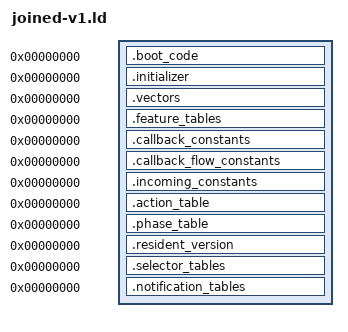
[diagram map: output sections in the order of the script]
OUTPUT_ARCH(riscv)
SECTIONS
{
 .boot_code 0 : SUBALIGN(2) { *(.boot_code)
  *(.text.tsl9_selector_storage_provider_e220)
  *(.text.tsl9_selector_notifications_block_e226)
  *(.text.tsl9_selector_notifications_block_e246)
  *(.text.tsl9_selector_notifications_block_e24a)
  *(.text.tsl9_selector_notifications_block_e252)
  *(.text.tsl9_selector_notifications_block_e254)
  *(.text.tsl9_selector_notifications_block_e260)
  *(.text.tsl9_selector_notifications_block_e26e)
  *(.text.tsl9_selector_notifications_block_e280)
  *(.text.tsl9_selector_notifications_block_e284)
  *(.text.tsl9_selector_notifications_block_e288)
  *(.text.tsl9_selector_notifications_block_e28c)
  *(.text.tsl9_selector_notifications_block_e290)
  *(.text.tsl9_selector_notifications_block_e29c)
  *(.text.tsl9_selector_notifications_block_e2a0)
  *(.text.tsl9_selector_notifications_block_e2a6)
  *(.text.tsl9_selector_notifications_block_e2aa)
  *(.text.tsl9_selector_notifications_block_e2b0)
  *(.text.tsl9_selector_notifications_block_e2b4)
  *(.text.tsl9_selector_notifications_block_e2bc)
  *(.text.tsl9_selector_notifications_block_e2ca)
  *(.text.tsl9_selector_notifications_block_e2da)
  *(.text.tsl9_selector_notifications_block_e2e2)
  *(.text.tsl9_selector_notifications_block_e2e8)
  *(.text.tsl9_selector_notifications_block_e2ea)
  *(.text.tsl9_selector_notifications_block_e2f0)
  *(.text.tsl9_selector_notifications_block_e2f8)
  *(.text.tsl9_selector_notifications_block_e30c)
  *(.text.tsl9_selector_notifications_block_e30e)
  *(.text.tsl9_selector_notifications_block_e310)
  *(.text.tsl9_selector_notifications_block_e314)
  *(.text.tsl9_selector_notifications_block_e316)
  *(.text.tsl9_selector_notifications_block_e31a)
  *(.text.tsl9_selector_notifications_block_e322)
  *(.text.tsl9_selector_notifications_block_e328)
  *(.text.tsl9_selector_notifications_block_e32c)
  *(.text.tsl9_selector_notifications_block_e330)
  *(.text.tsl9_selector_notifications_block_e336)
  *(.text.tsl9_selector_notifications_block_e33c)
  *(.text.tsl9_selector_notifications_block_e342)
  *(.text.tsl9_selector_notifications_block_e34c)
  *(.text.tsl9_selector_notifications_block_e350)
  *(.text.tsl9_selector_notifications_block_e352)
  *(.text.tsl9_selector_notifications_block_e358)
  *(.text.tsl9_selector_notifications_block_e35c)
  *(.text.tsl9_selector_notifications_block_e362)
  *(.text.tsl9_selector_notifications_block_e36c)
  *(.text.tsl9_selector_notifications_block_e36e)
  *(.text.tsl9_selector_notifications_block_e374)
  *(.text.tsl9_selector_notifications_block_e37e)
  *(.text.tsl9_selector_notifications_block_e380)
  *(.text.tsl9_selector_notifications_block_e388)
  *(.text.tsl9_selector_notifications_block_e38c)
  *(.text.tsl9_selector_notifications_block_e394)
  *(.text.tsl9_selector_notifications_block_e398)
  *(.text.tsl9_selector_notifications_block_e3a2)
  *(.text.tsl9_selector_notifications_block_e3a6)
  *(.text.tsl9_selector_notifications_block_e3a8)
  *(.text.tsl9_selector_notifications_block_e3b0)
  *(.text.tsl9_selector_notifications_block_e3bc)
  *(.text.tsl9_selector_notifications_block_e3be)
  *(.text.tsl9_selector_notifications_block_e3c6)
  *(.text.tsl9_selector_notifications_block_e3ca)
  *(.text.tsl9_selector_notifications_block_e3d2)
  *(.text.tsl9_selector_notifications_block_e3dc)
  *(.text.tsl9_selector_notifications_block_e3de)
  *(.text.tsl9_selector_notifications_block_e3e8)
  *(.text.tsl9_selector_notifications_block_e3f0)
  *(.text.tsl9_selector_notifications_block_e3f2)
  *(.text.tsl9_selector_notifications_block_e3f6)
  *(.text.tsl9_selector_notifications_block_e3f8)
  *(.text.tsl9_selector_notifications_block_e3fe)
  *(.text.tsl9_selector_notifications_block_e404)
  *(.text.tsl9_selector_notifications_block_e40a)
  *(.text.tsl9_selector_notifications_block_e410)
  *(.text.tsl9_selector_notifications_block_e416)
  *(.text.tsl9_selector_notifications_block_e41a)
  *(.text.tsl9_selector_notifications_block_e420)
  *(.text.tsl9_selector_notifications_block_e424)
  *(.text.tsl9_selector_notifications_block_e428)
  *(.text.tsl9_selector_notifications_block_e42e)
  *(.text.tsl9_selector_notifications_block_e432)
  *(.text.tsl9_selector_notifications_block_e438)
  *(.text.tsl9_selector_notifications_block_e43c)
  *(.text.tsl9_selector_notifications_block_e442)
  *(.text.tsl9_selector_notifications_block_e446)
  *(.text.tsl9_selector_notifications_block_e44c)
  *(.text.tsl9_selector_notifications_block_e450)
  *(.text.tsl9_selector_notifications_block_e454)
  *(.text.tsl9_selector_notifications_block_e458)
  *(.text.tsl9_selector_notifications_block_e45c)
  *(.text.tsl9_selector_notifications_block_e464)
  *(.text.tsl9_selector_notifications_block_e466)
  *(.text.tsl9_selector_notifications_block_e46c)
  *(.text.tsl9_selector_notifications_block_e472)
  *(.text.tsl9_selector_notifications_block_e47a)
  *(.text.tsl9_selector_notifications_block_e47e)
  *(.text.tsl9_selector_notifications_block_e482)
  *(.text.tsl9_selector_notifications_block_e486)
  *(.text.tsl9_selector_notifications_block_e48e)
  *(.text.tsl9_selector_notifications_block_e492)
  *(.text.tsl9_selector_notifications_block_e49a)
  *(.text.tsl9_selector_notifications_block_e49e)
  *(.text.tsl9_selector_notifications_block_e4a0)
  *(.text.tsl9_selector_notifications_block_e4a8)
  *(.text.tsl9_selector_notifications_block_e4b0)
  *(.text.tsl9_selector_notifications_block_e4b4)
  *(.text.tsl9_selector_notifications_block_e4b6)
  *(.text.tsl9_selector_notifications_block_e4c2)
  *(.text.tsl9_selector_notifications_block_e4c8)
  *(.text.tsl9_selector_notifications_block_e4ca)
  *(.text.tsl9_selector_notifications_block_e4d2)
  *(.text.tsl9_selector_notifications_block_e4d6)
  *(.text.tsl9_selector_notifications_block_e4da)
  *(.text.tsl9_selector_notifications_block_e4de)
  *(.text.tsl9_selector_notifications_block_e4e6)
  *(.text.tsl9_selector_notifications_block_e4ea)
  *(.text.tsl9_selector_notifications_block_e4ee)
  *(.text.tsl9_selector_notifications_block_e4f2)
  *(.text.tsl9_selector_notifications_block_e4fa)
  *(.text.tsl9_selector_notifications_block_e4fe)
  *(.text.tsl9_selector_notifications_block_e502)
  *(.text.tsl9_selector_notifications_block_e506)
  *(.text.tsl9_selector_notifications_block_e50a)
  *(.text.tsl9_selector_notifications_block_e50e)
  *(.text.tsl9_selector_notifications_block_e516)
  *(.text.tsl9_selector_notifications_block_e51a)
  *(.text.tsl9_selector_notifications_block_e520)
  *(.text.tsl9_selector_notifications_block_e524)
  *(.text.tsl9_selector_notifications_block_e532)
  *(.text.tsl9_selector_notifications_block_e53a)
  *(.text.tsl9_selector_notifications_block_e53e)
  *(.text.tsl9_selector_notifications_block_e546)
  *(.text.tsl9_selector_notifications_block_e554)
  *(.text.tsl9_selector_notifications_block_e55c)
  *(.text.tsl9_selector_notifications_block_e560)
  *(.text.tsl9_selector_notifications_block_e568)
  *(.text.tsl9_selector_notifications_block_e570)
  *(.text.tsl9_selector_notifications_block_e578)
  *(.text.tsl9_selector_notifications_block_e580)
  *(.text.tsl9_selector_notifications_block_e584)
  *(.text.tsl9_selector_notifications_block_e592)
  *(.text.tsl9_selector_notifications_block_e59a)
  *(.text.tsl9_selector_notifications_block_e5a2)
  *(.text.tsl9_selector_notifications_block_e5a8)
  *(.text.tsl9_selector_notifications_block_e5ac)
  *(.text.tsl9_selector_notifications_block_e5b0)
  *(.text.tsl9_selector_notifications_block_e5b2)
  *(.text.tsl9_selector_notifications_block_e5ba)
  *(.text.tsl9_selector_notifications_block_e5be)
  *(.text.tsl9_selector_notifications_block_e5c6)
  *(.text.tsl9_selector_notifications_block_e5c8)
  *(.text.tsl9_selector_notifications_block_e5d0)
  *(.text.tsl9_selector_notifications_block_e5d8)
  *(.text.tsl9_selector_notifications_block_e5e8)
  *(.text.tsl9_selector_notifications_block_e5ee)
  *(.text.tsl9_selector_notifications_block_e5f2)
  *(.text.tsl9_selector_notifications_block_e5f6)
  *(.text.tsl9_selector_notifications_block_e5f8)
  *(.text.tsl9_selector_notifications_block_e5fe)
  *(.text.tsl9_selector_notifications_block_e606)
  *(.text.tsl9_selector_notifications_block_e60c)
  *(.text.tsl9_selector_notifications_block_e616)
  *(.text.tsl9_selector_notifications_block_e61c)
  *(.text.tsl9_selector_notifications_block_e628)
  *(.text.tsl9_selector_notifications_block_e634)
  *(.text.tsl9_selector_notifications_block_e640)
  *(.text.tsl9_selector_notifications_block_e642)
  *(.text.tsl9_selector_notifications_block_e64e)
  *(.text.tsl9_selector_notifications_block_e654)
  *(.text.tsl9_selector_notifications_block_e65a)
  *(.text.tsl9_selector_notifications_block_e66a)
  *(.text.tsl9_selector_notifications_block_e670)
  *(.text.tsl9_selector_notifications_block_e672)
  *(.text.tsl9_selector_notifications_block_e67e)
  *(.text.tsl9_selector_notifications_block_e684)
  *(.text.tsl9_selector_notifications_block_e692)
  *(.text.tsl9_selector_notifications_block_e69e)
  *(.text.tsl9_selector_notifications_block_e6a2)
  *(.text.tsl9_selector_notifications_block_e6a8)
  *(.text.tsl9_selector_notifications_block_e6b0)
  *(.text.tsl9_selector_notifications_block_e6b4)
  *(.text.tsl9_selector_notifications_block_e6b6)
  *(.text.tsl9_selector_notifications_block_e6c8)
  *(.text.tsl9_selector_notifications_block_e6ce)
  *(.text.tsl9_selector_notifications_block_e6dc)
  *(.text.tsl9_selector_notifications_block_e6e0)
  *(.text.tsl9_selector_notifications_block_e6e2)
  *(.text.tsl9_selector_notifications_block_e6ec)
  *(.text.tsl9_selector_notifications_block_e6ee)
  *(.text.tsl9_selector_notifications_block_e6f2)
  *(.text.tsl9_selector_notifications_block_e6f4)
  *(.text.tsl9_selector_notifications_block_e6f8)
  *(.text.tsl9_selector_notifications_block_e6fa)
  *(.text.tsl9_selector_notifications_block_e700)
  *(.text.tsl9_selector_notifications_block_e706)
  *(.text.tsl9_selector_notifications_block_e70c)
  *(.text.tsl9_selector_notifications_block_e712)
  *(.text.tsl9_selector_notifications_block_e71a)
  *(.text.tsl9_selector_notifications_block_e71e)
  *(.text.tsl9_selector_notifications_block_e724)
  *(.text.tsl9_selector_notifications_block_e728)
  *(.text.tsl9_selector_notifications_block_e72e)
  *(.text.tsl9_selector_notifications_block_e736)
  *(.text.tsl9_selector_notifications_block_e742)
  *(.text.tsl9_selector_notifications_block_e750)
  *(.text.tsl9_selector_notifications_block_e756)
  *(.text.tsl9_selector_notifications_block_e75c)
  *(.text.tsl9_selector_notifications_block_e760)
  *(.text.tsl9_selector_notifications_block_e762)
  *(.text.tsl9_selector_notifications_block_e768)
  *(.text.tsl9_selector_notifications_block_e76e)
  *(.text.tsl9_selector_notifications_block_e770)
  *(.text.tsl9_selector_notifications_block_e776)
  *(.text.tsl9_selector_notifications_block_e782)
  *(.text.tsl9_selector_notifications_block_e786)
  *(.text.tsl9_selector_notifications_block_e788)
  *(.text.tsl9_selector_notifications_block_e790)
  *(.text.tsl9_selector_notifications_block_e794)
  *(.text.tsl9_selector_notifications_block_e79c)
  *(.text.tsl9_selector_notifications_block_e7a4)
  *(.text.tsl9_selector_notifications_block_e7b4)
  *(.text.tsl9_selector_notifications_block_e7ba)
  *(.text.tsl9_selector_notifications_block_e7be)
  *(.text.tsl9_selector_notifications_block_e7c4)
  *(.text.tsl9_selector_notifications_block_e7c8)
  *(.text.tsl9_selector_notifications_block_e7cc)
  *(.text.tsl9_selector_notifications_block_e7d0)
  *(.text.tsl9_selector_notifications_block_e7e0)
  *(.text.tsl9_selector_notifications_block_e7e6)
  *(.text.tsl9_selector_notifications_block_e7ea)
  *(.text.tsl9_selector_notifications_block_e7f0)
  *(.text.tsl9_selector_notifications_block_e7f6)
  *(.text.tsl9_selector_notifications_block_e7fc)
  *(.text.tsl9_selector_notifications_block_e802)
  *(.text.tsl9_selector_notifications_block_e808)
  *(.text.tsl9_selector_notifications_block_e816)
  *(.text.tsl9_selector_notifications_block_e828)
  *(.text.tsl9_selector_notifications_block_e82c)
  *(.text.tsl9_selector_notifications_block_e832)
  *(.text.tsl9_selector_notifications_block_e838)
  *(.text.tsl9_selector_notifications_block_e83a)
  *(.text.tsl9_selector_notifications_block_e83e)
  *(.text.tsl9_selector_notifications_block_e842)
  *(.text.tsl9_selector_notifications_block_e848)
  *(.text.tsl9_selector_notifications_block_e84e)
  *(.text.tsl9_selector_notifications_block_e854)
  *(.text.tsl9_selector_notifications_block_e858)
  *(.text.tsl9_selector_notifications_block_e85c)
  *(.text.tsl9_selector_notifications_block_e862)
  *(.text.tsl9_selector_notifications_block_e868)
  *(.text.tsl9_selector_notifications_block_e86e)
  *(.text.tsl9_selector_notifications_block_e874)
  *(.text.tsl9_selector_notifications_block_e87a)
  *(.text.tsl9_selector_notifications_block_e880)
  *(.text.tsl9_selector_notifications_block_e884)
  *(.text.tsl9_selector_notifications_block_e888)
  *(.text.tsl9_selector_notifications_block_e88c)
  *(.text.tsl9_selector_notifications_block_e890)
  *(.text.tsl9_selector_notifications_block_e896)
  *(.text.tsl9_selector_notifications_block_e89c)
  *(.text.tsl9_selector_notifications_block_e8a2)
  *(.text.tsl9_selector_notifications_block_e8a8)
  *(.text.tsl9_selector_notifications_block_e8ae)
  *(.text.tsl9_selector_notifications_block_e8b4)
  *(.text.tsl9_selector_notifications_block_e8ba)
  *(.text.tsl9_selector_notifications_block_e8c0)
  *(.text.tsl9_selector_notifications_block_e8c4)
  *(.text.tsl9_selector_notifications_block_e8d2)
  *(.text.tsl9_selector_notifications_block_e8d4)
  *(.text.tsl9_selector_notifications_block_e8da)
  *(.text.tsl9_selector_notifications_block_e8de)
  *(.text.tsl9_selector_notifications_block_e8e4)
  *(.text.tsl9_selector_notifications_block_e8e8)
  *(.text.tsl9_selector_notifications_block_e8f2)
  *(.text.tsl9_selector_notifications_block_e8f4)
  *(.text.tsl9_selector_notifications_block_e8fa)
  *(.text.tsl9_selector_notifications_block_e904)
  *(.text.tsl9_selector_notifications_block_e906)
  *(.text.tsl9_selector_notifications_block_e90c)
  *(.text.tsl9_selector_notifications_block_e910)
  *(.text.tsl9_selector_notifications_block_e91a)
  *(.text.tsl9_selector_notifications_block_e91c)
  *(.text.tsl9_selector_notifications_block_e924)
  *(.text.tsl9_selector_notifications_block_e930)
  *(.text.tsl9_selector_notifications_block_e932)
  *(.text.tsl9_selector_notifications_block_e936)
  *(.text.tsl9_selector_notifications_block_e93a)
  *(.text.tsl9_selector_notifications_block_e940)
  *(.text.tsl9_selector_notifications_block_e946)
  *(.text.tsl9_selector_notifications_block_e94c)
  *(.text.tsl9_selector_notifications_block_e950)
  *(.text.tsl9_selector_notifications_block_e952)
  *(.text.tsl9_selector_notifications_block_e958)
  *(.text.tsl9_selector_notifications_block_e964)
  *(.text.tsl9_selector_notifications_block_e976)
  *(.text.tsl9_selector_notifications_block_e97e)
  *(.text.tsl9_selector_notifications_block_e982)
  *(.text.tsl9_selector_notifications_block_e988)
  *(.text.tsl9_selector_notifications_block_e98c)
  *(.text.tsl9_selector_notifications_block_e992)
  *(.text.tsl9_selector_notifications_block_e99a)
  *(.text.tsl9_selector_notifications_block_e9ac)
  *(.text.tsl9_selector_notifications_block_e9b0)
  *(.text.tsl9_selector_notifications_block_e9be)
  *(.text.tsl9_selector_notifications_block_e9c6)
  *(.text.tsl9_selector_notifications_block_e9ca)
  *(.text.tsl9_selector_notifications_block_e9d6)
  *(.text.tsl9_selector_notifications_block_e9da)
  *(.text.tsl9_selector_notifications_block_e9dc)
  *(.text.tsl9_selector_notifications_block_e9e4)
  *(.text.tsl9_selector_notifications_block_e9e8)
  *(.text.tsl9_selector_notifications_block_e9f0)
  *(.text.tsl9_selector_notifications_block_e9f4)
  *(.text.tsl9_selector_notifications_block_ea00)
  *(.text.tsl9_selector_notifications_block_ea02)
  *(.text.tsl9_selector_notifications_block_ea0a)
  *(.text.tsl9_selector_notifications_block_ea0e)
  *(.text.tsl9_selector_notifications_block_ea18)
  *(.text.tsl9_selector_notifications_block_ea1a)
  *(.text.tsl9_selector_notifications_block_ea1e)
  *(.text.tsl9_selector_notifications_block_ea22)
  *(.text.tsl9_selector_notifications_block_ea24)
  *(.text.tsl9_selector_notifications_block_ea2a)
  *(.text.tsl9_selector_notifications_block_ea2e)
  *(.text.tsl9_selector_notifications_block_ea32)
  *(.text.tsl9_selector_notifications_block_ea36)
  *(.text.tsl9_selector_notifications_block_ea3a)
  *(.text.tsl9_selector_notifications_block_ea40)
  *(.text.tsl9_selector_notifications_block_ea46)
  *(.text.tsl9_selector_notifications_block_ea4c)
  *(.text.tsl9_selector_notifications_block_ea5c)
  *(.text.tsl9_selector_notifications_block_ea6e)
  *(.text.tsl9_selector_notifications_block_ea74)
  *(.text.tsl9_selector_notifications_block_ea78)
  *(.text.tsl9_selector_notifications_block_ea7e)
  *(.text.tsl9_selector_notifications_block_ea84)
  *(.text.tsl9_selector_notifications_block_ea88)
  *(.text.tsl9_selector_notifications_block_ea8c)
  *(.text.tsl9_selector_notifications_block_ea90)
  *(.text.tsl9_selector_notifications_block_ea94)
  *(.text.tsl9_selector_notifications_block_ea9a)
  *(.text.tsl9_selector_notifications_block_eaa0)
  *(.text.tsl9_selector_notifications_block_eaa6)
  *(.text.tsl9_selector_notifications_block_eaac)
  *(.text.tsl9_selector_notifications_block_eab2)
  *(.text.tsl9_selector_notifications_block_eab8)
  *(.text.tsl9_selector_notifications_block_eabe)
  *(.text.tsl9_selector_notifications_block_eac4)
  *(.text.tsl9_selector_notifications_block_eaca)
  *(.text.tsl9_selector_notifications_block_ead0)
  *(.text.tsl9_selector_notifications_block_ead6)
  *(.text.tsl9_selector_notifications_block_eadc)
  *(.text.tsl9_selector_notifications_block_eae2)
  *(.text.tsl9_selector_notifications_block_eae6)
  *(.text.tsl9_selector_notifications_block_eaea)
  *(.text.tsl9_selector_notifications_block_eaee)
  *(.text.tsl9_selector_notifications_block_eb02)
  *(.text.tsl9_selector_notifications_block_eb06)
  *(.text.tsl9_selector_notifications_block_eb08)
  *(.text.tsl9_selector_notifications_block_eb0e)
  *(.text.tsl9_selector_notifications_block_eb24)
  *(.text.tsl9_selector_notifications_block_eb2a)
  *(.text.tsl9_selector_notifications_block_eb2e)
  *(.text.tsl9_selector_notifications_block_eb32)
  *(.text.tsl9_selector_notifications_block_eb38)
  *(.text.tsl9_selector_notifications_block_eb3a)
  *(.text.tsl9_selector_notifications_block_eb4c)
  *(.text.tsl9_selector_notifications_block_eb54)
  *(.text.tsl9_selector_notifications_block_eb5c)
  *(.text.tsl9_selector_notifications_block_eb64)
  *(.text.tsl9_selector_notifications_block_eb6c)
  *(.text.tsl9_selector_notifications_block_eb8a)
  *(.text.tsl9_selector_notifications_block_eb8e)
  *(.text.tsl9_selector_notifications_block_eb92)
  *(.text.tsl9_selector_notifications_block_eba0)
  *(.text.tsl9_selector_notifications_block_eba4)
  *(.text.tsl9_selector_notifications_block_ebaa)
 }
 .initializer 0 : SUBALIGN(4) { *(.initializer) }
 .vectors 0 : SUBALIGN(4) { *(.vectors) }
 .feature_tables 0 : SUBALIGN(4) { *(.feature_tables) }
 .callback_constants 0 : SUBALIGN(4) { *(.callback_constants) }
 .callback_flow_constants 0 : SUBALIGN(4) { *(.callback_flow_constants) }
 .incoming_constants 0 : SUBALIGN(4) { *(.incoming_constants) }
 .action_table 0 : SUBALIGN(4) { *(.action_table) }
 .phase_table 0 : SUBALIGN(4) { *(.phase_table) }
 .resident_version 0 : SUBALIGN(4) { *(.resident_version) }
 .selector_tables 0 : SUBALIGN(1) {
  *(.rodata.tsl9_feature_state_records_static_data_1a4e4)
  *(.rodata.tsl9_feature_state_records_static_data_1a518)
  *(.rodata.tsl9_feature_state_records_static_data_1a528)
  *(.rodata.tsl9_feature_state_records_static_data_1a538)
 }
 .notification_tables 0 : SUBALIGN(4) {
  *(.rodata.tsl9_selector_notifications_table_1a13c)
  *(.rodata.tsl9_selector_notifications_table_1a150)
  *(.rodata.tsl9_selector_notifications_table_1a1c8)
  *(.rodata.tsl9_selector_notifications_table_1a314)
  *(.rodata.tsl9_selector_notifications_table_1a33c)
 }
 /DISCARD/ : { *(.comment) *(.riscv.attributes) *(.llvm_addrsig) }
}
